AUTOSAR XML (schema 4-2-2)
package /STELLANTIS/EPT/ASWCs
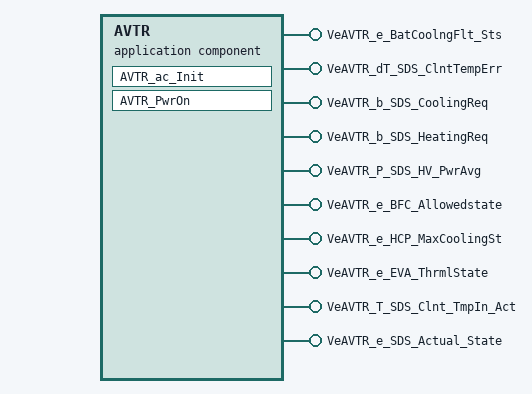
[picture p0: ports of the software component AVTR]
  application sw component type AVTR
    10 x provide port:
      VeAVTR_e_BatCoolngFlt_Sts: nonqueued-sender-com-spec{data-element=Value, init-value=0}, provided-interface=VeAVTR_e_BatCoolngFlt_Sts
      VeAVTR_dT_SDS_ClntTempErr: nonqueued-sender-com-spec{data-element=Value, init-value=0}, provided-interface=VeAVTR_dT_SDS_ClntTempErr
      VeAVTR_b_SDS_CoolingReq: nonqueued-sender-com-spec{data-element=Value, init-value=0}, provided-interface=VeAVTR_b_SDS_CoolingReq
      VeAVTR_b_SDS_HeatingReq: nonqueued-sender-com-spec{data-element=Value, init-value=0}, provided-interface=VeAVTR_b_SDS_HeatingReq
      VeAVTR_P_SDS_HV_PwrAvg: nonqueued-sender-com-spec{data-element=Value, init-value=0}, provided-interface=VeAVTR_P_SDS_HV_PwrAvg
      VeAVTR_e_BFC_Allowedstate: nonqueued-sender-com-spec{data-element=Value, init-value=CeAVTR_e_BFC_NotAllowed}, provided-interface=VeAVTR_e_BFC_Allowedstate
      VeAVTR_e_HCP_MaxCoolingSt: nonqueued-sender-com-spec{data-element=Value, init-value=CeAVTR_e_HCP_MaxCoolingOFF}, provided-interface=VeAVTR_e_HCP_MaxCoolingSt
      VeAVTR_e_EVA_ThrmlState: nonqueued-sender-com-spec{data-element=Value, init-value=CeAVTR_e_NoEVACond}, provided-interface=VeAVTR_e_EVA_ThrmlState
      VeAVTR_T_SDS_Clnt_TmpIn_Act: nonqueued-sender-com-spec{data-element=Value, init-value=0}, provided-interface=VeAVTR_T_SDS_Clnt_TmpIn_Act
      VeAVTR_e_SDS_Actual_State: nonqueued-sender-com-spec{data-element=Value, init-value=CeTRIR_e_SDS_OFF}, provided-interface=VeAVTR_e_SDS_Actual_State
    behavior IB_AVTR: data-type-mapping=msADTtoIDTMapping, handle-termination-and-restart=NO-SUPPORT
      init event Event_AVTR_ac_Init: start-on-event=AVTR_ac_Init
      init event Event_PwrOn: start-on-event=AVTR_PwrOn
      runnable AVTR_ac_Init
        data-send-points:
          4 x access:
            OUT_VeAVTR_e_BFC_Allowedstate_Value: accessed-variable=VeAVTR_e_BFC_Allowedstate.Value
            OUT_VeAVTR_e_HCP_MaxCoolingSt_Value: accessed-variable=VeAVTR_e_HCP_MaxCoolingSt.Value
            OUT_VeAVTR_e_EVA_ThrmlState_Value: accessed-variable=VeAVTR_e_EVA_ThrmlState.Value
            OUT_VeAVTR_e_SDS_Actual_State_Value: accessed-variable=VeAVTR_e_SDS_Actual_State.Value
      runnable AVTR_PwrOn
        data-send-points:
          10 x access:
            OUT_VeAVTR_e_BatCoolngFlt_Sts_Value: accessed-variable=VeAVTR_e_BatCoolngFlt_Sts.Value
            OUT_VeAVTR_dT_SDS_ClntTempErr_Value: accessed-variable=VeAVTR_dT_SDS_ClntTempErr.Value
            OUT_VeAVTR_b_SDS_CoolingReq_Value: accessed-variable=VeAVTR_b_SDS_CoolingReq.Value
            OUT_VeAVTR_b_SDS_HeatingReq_Value: accessed-variable=VeAVTR_b_SDS_HeatingReq.Value
            OUT_VeAVTR_P_SDS_HV_PwrAvg_Value: accessed-variable=VeAVTR_P_SDS_HV_PwrAvg.Value
            OUT_VeAVTR_e_BFC_Allowedstate_Value: accessed-variable=VeAVTR_e_BFC_Allowedstate.Value
            OUT_VeAVTR_e_HCP_MaxCoolingSt_Value: accessed-variable=VeAVTR_e_HCP_MaxCoolingSt.Value
            OUT_VeAVTR_e_EVA_ThrmlState_Value: accessed-variable=VeAVTR_e_EVA_ThrmlState.Value
            OUT_VeAVTR_T_SDS_Clnt_TmpIn_Act_Value: accessed-variable=VeAVTR_T_SDS_Clnt_TmpIn_Act.Value
            OUT_VeAVTR_e_SDS_Actual_State_Value: accessed-variable=VeAVTR_e_SDS_Actual_State.Value
      variation point proxy Variant_AVTR_1: category=CONDITION, condition-access=0
